# DA14580 register map
Vendor: Dialog; Series: DA14580x; File version: 1.2
CPU: CM0 r1p0, little endian, MPU, FPU, 3 interrupt priority bits
Registers are 16-bit, read-write, reset 0x0 unless marked. A register's access mark holds for its fields unless they carry their own. Offsets are from the block's base; [hi:lo] are bit positions; <NAME> marks a mode.

## riscutil580_gpreg_nl01 — riscutil580_gpreg_nl01 registers
Base 0x50003300
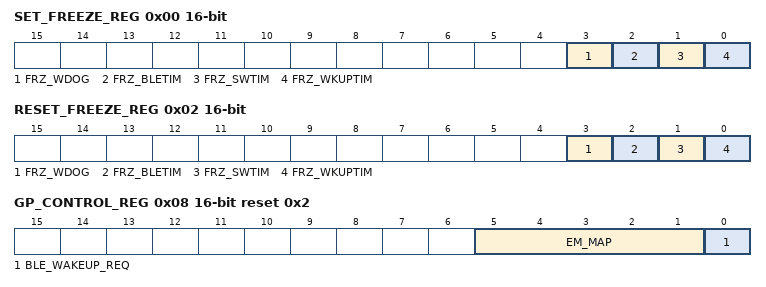
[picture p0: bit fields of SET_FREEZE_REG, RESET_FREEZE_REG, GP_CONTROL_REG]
0x00 SET_FREEZE_REG — Controls freezing of various timers/counters.
  [3] FRZ_WDOG — If '1', the watchdog timer is frozen, '0' is discarded. WATCHDOG_CTRL_REG[NMI_RST] must be '0' to allow the freeze function.
  [2] FRZ_BLETIM — If '1', the BLE master clock is frozen, '0' is discarded.
  [1] FRZ_SWTIM — If '1', the SW Timer (TIMER0) is frozen, '0' is discarded.
  [0] FRZ_WKUPTIM — If '1', the Wake Up Timer is frozen, '0' is discarded.
0x02 RESET_FREEZE_REG — Controls unfreezing of various timers/counters.
  [3] FRZ_WDOG — If '1', the watchdog timer continues, '0' is discarded.
  [2] FRZ_BLETIM — If '1', the the BLE master clock continues, '0' is discarded.
  [1] FRZ_SWTIM — If '1', the SW Timer (TIMER0) continues, '0' is discarded.
  [0] FRZ_WKUPTIM — If '1', the Wake Up Timer continues, '0' is discarded.
0x04 DEBUG_REG reset 0x1 — Various debug information register.
  [0] DEBUGS_FREEZE_EN — Default '1', freezing of the on-chip timers is enabled when the Cortex-M0 is halted in DEBUG State. If '0', freezing of the on-chip timers is depending on FREEZE_REG when the Cortex-M0 is halted in DEBUG State except the watchdog timer. The watchdog timer is always frozen when the Cortex-M0 is halted in DEBUG State.
0x06 GP_STATUS_REG — General purpose system status register.
  [0] CAL_PHASE — If '1', it designates that the chip is in Calibration Phase i.e. the OTP has been initially programmed but no Calibration has occured.
0x08 GP_CONTROL_REG reset 0x2 — General purpose system control register.
  [5:1] EM_MAP — Select the mapping of the Exchange memory pages. 0: EM size 0 kB, SysRAM size 42 kB 1: EM size 2 kB, SysRAM size 48 kB 2: EM size 3 kB, SysRAM size 47 kB 3: EM size 4 kB, SysRAM size 46 kB 4: EM size 5 kB, SysRAM size 45 kB 5: EM size 6 kB, SysRAM size 44 kB 6: EM size 7 kB, SysRAM size 43 kB 7: EM size 8 kB, SysRAM size 42 kB 8: Reserved 9: EM size 4 kB, SysRAM size 40 kB 10: EM size 5 kB, SysRAM size 40 kB 11: EM size 6 kB, SysRAM size 40 kB 12: EM size 7 kB, SysRAM size 40 kB 13: EM size 8 kB, SysRAM size 40 kB 14: EM size 9 kB, SysRAM size 40 kB 15: EM size 10 kB, SysRAM size 40 kB 16: Reserved 17: EM size 6 kB, SysRAM size 38 kB 18: EM size 7 kB, SysRAM size 38 kB 19: EM size 8 kB, SysRAM size 38 kB 20: EM size 9 kB, SysRAM size 38 kB 21: EM size 10 kB, SysRAM size 38 kB 22: EM size 11 kB, SysRAM size 38 kB 23: EM size 12 kB, SysRAM size 38 kB other: Reserved.
  [0] BLE_WAKEUP_REQ — If '1', the BLE wakes up. Must be kept high at least for 1 low power clock period. If the BLE is in deep sleep state, then by setting this bit it will cause the wakeup LP IRQ to be asserted with a delay of 3 to 4 low power cycles.

## riscutil580_wdog_nl00 — riscutil580_wdog_nl00 registers
Base 0x50003100
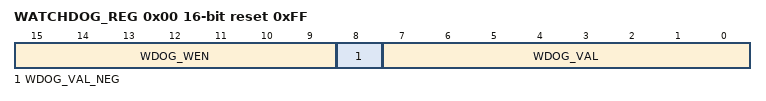
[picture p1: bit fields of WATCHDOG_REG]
0x00 WATCHDOG_REG reset 0xFF — Watchdog timer register.
  [15:9] WDOG_WEN wo — 0000.000 = Write enable for Watchdog timer else Write disable. This filter prevents unintentional presetting the watchdog with a SW run-away.
  [8] WDOG_VAL_NEG — 0 = Watchdog timer value is positive. 1 = Watchdog timer value is negative.
  [7:0] WDOG_VAL — Write: Watchdog timer reload value. Note that all bits 15-9 must be 0 to reload this register. Read: Actual Watchdog timer value. Decremented by 1 every 10.24 msec. Bit 8 indicates a negative counter value. 2, 1, 0, 1FF16, 1FE16 etc. An NMI or WDOG (SYS) reset is generated under the following conditions: If WATCHDOG_CTRL_REG[NMI_RST] = 0 then If WDOG_VAL = 0 -> NMI (Non Maskable Interrupt) if WDOG_VAL = 1F016 -> WDOG reset -> reload FF16 If WATCHDOG_CTRL_REG[NMI_RST] = 1 then if WDOG_VAL <= 0 -> WDOG reset -> reload FF16
0x02 WATCHDOG_CTRL_REG — Watchdog control register.
  [0] NMI_RST — 0 = Watchdog timer generates NMI at value 0, and WDOG (SYS) reset at <=-16. Timer can be frozen /resumed using SET_FREEZE_REG[FRZ_WDOG]/ RESET_FREEZE_REG[FRZ_WDOG]. 1 = Watchdog timer generates a WDOG (SYS) reset at value 0 and can not be frozen by Software. Note that this bit can only be set to 1 by SW and only be reset with a WDOG (SYS) reset or SW reset. The watchdog is always frozen when the Cortex-M0 is halted in DEBUG State.
